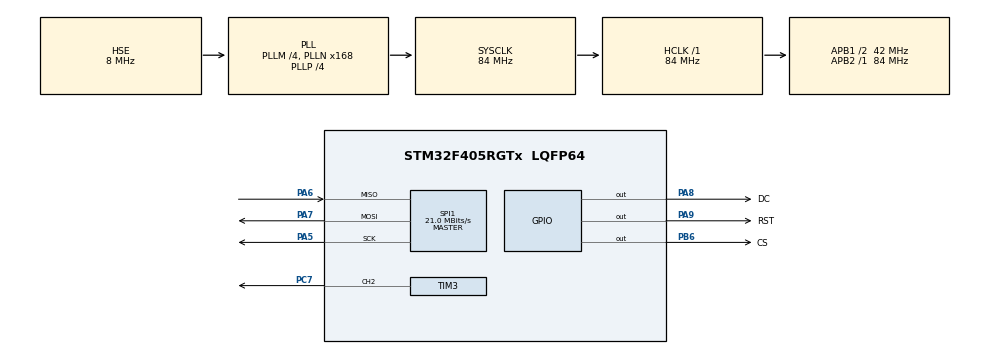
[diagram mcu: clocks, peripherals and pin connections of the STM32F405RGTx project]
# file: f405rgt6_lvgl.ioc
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FREERTOS.Tasks01=defaultTask,24,128,StartDefaultTask,Default,NULL,Dynamic,NULL,NULL
Mcu.Family=STM32F4
Mcu.Name=STM32F405RGTx
Mcu.Package=LQFP64
NVIC.PriorityGroup=NVIC_PRIORITYGROUP_4
NVIC.TIM1_UP_TIM10_IRQn=true\:15\:0\:false\:false\:true\:false\:false\:true\:true
NVIC.TimeBase=TIM1_UP_TIM10_IRQn
NVIC.TimeBaseIP=TIM1
PA5.Mode=Full_Duplex_Master
PA5.Signal=SPI1_SCK
PA6.Mode=Full_Duplex_Master
PA6.Signal=SPI1_MISO
PA7.Mode=Full_Duplex_Master
PA7.Signal=SPI1_MOSI
PA8.GPIO_Label=DC
PA8.PinState=GPIO_PIN_SET
PA8.Signal=GPIO_Output
PA9.GPIO_Label=RST
PA9.PinState=GPIO_PIN_SET
PA9.Signal=GPIO_Output
PB6.GPIO_Label=CS
PB6.PinState=GPIO_PIN_SET
PB6.Signal=GPIO_Output
PC14-OSC32_IN.Mode=LSE-External-Oscillator
PC14-OSC32_IN.Signal=RCC_OSC32_IN
PC15-OSC32_OUT.Mode=LSE-External-Oscillator
PC15-OSC32_OUT.Signal=RCC_OSC32_OUT
PC7.Signal=S_TIM3_CH2
PH0-OSC_IN.Mode=HSE-External-Oscillator
PH0-OSC_IN.Signal=RCC_OSC_IN
PH1-OSC_OUT.Mode=HSE-External-Oscillator
PH1-OSC_OUT.Signal=RCC_OSC_OUT
ProjectManager.HeapSize=0x200
ProjectManager.StackSize=0x400
ProjectManager.TargetToolchain=Makefile
RCC.48MHZClocksFreq_Value=84000000
RCC.AHBFreq_Value=84000000
RCC.APB1CLKDivider=RCC_HCLK_DIV2
RCC.APB1Freq_Value=42000000
RCC.APB1TimFreq_Value=84000000
RCC.APB2Freq_Value=84000000
RCC.APB2TimFreq_Value=84000000
RCC.CortexFreq_Value=84000000
RCC.HCLKFreq_Value=84000000
RCC.HSE_VALUE=8000000
RCC.HSI_VALUE=16000000
RCC.PLLM=4
RCC.PLLN=168
RCC.PLLP=RCC_PLLP_DIV4
RCC.PLLSourceVirtual=RCC_PLLSOURCE_HSE
RCC.SYSCLKFreq_VALUE=84000000
RCC.SYSCLKSource=RCC_SYSCLKSOURCE_PLLCLK
RCC.VCOOutputFreq_Value=336000000
SH.S_TIM3_CH2.0=TIM3_CH2,PWM Generation2 CH2
SPI1.BaudRatePrescaler=SPI_BAUDRATEPRESCALER_4
SPI1.CLKPolarity=SPI_POLARITY_LOW
SPI1.CalculateBaudRate=21.0 MBits/s
SPI1.DataSize=SPI_DATASIZE_8BIT
SPI1.Direction=SPI_DIRECTION_2LINES
SPI1.Mode=SPI_MODE_MASTER
SPI1.VirtualType=VM_MASTER
TIM3.Channel-PWM\ Generation2\ CH2=TIM_CHANNEL_2
TIM3.Period=1000-1
TIM3.Prescaler=300-1
VP_FREERTOS_VS_CMSIS_V2.Mode=CMSIS_V2
VP_SYS_VS_tim1.Mode=TIM1
board=custom

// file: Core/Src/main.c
/* USER CODE BEGIN Header */
/**
  ******************************************************************************
  * @file           : main.c
  * @brief          : Main program body
  ******************************************************************************
  * @attention
  *
  * Copyright (c) 2024 STMicroelectronics.
  * All rights reserved.
  *
  * This software is licensed under terms that can be found in the LICENSE file
  * in the root directory of this software component.
  * If no LICENSE file comes with this software, it is provided AS-IS.
  *
  ******************************************************************************
  */
/* USER CODE END Header */
#include "main.h"
#include "cmsis_os.h"
#include "spi.h"
#include "tim.h"
#include "gpio.h"

void SystemClock_Config(void);
void MX_FREERTOS_Init(void);

int main(void)
{
  /* USER CODE BEGIN 1 */
  __HAL_RCC_HSI_ENABLE();
  __HAL_RCC_SYSCLK_CONFIG(RCC_SYSCLKSOURCE_HSI);
  /* USER CODE END 1 */

  /* MCU Configuration--------------------------------------------------------*/

  /* Reset of all peripherals, Initializes the Flash interface and the Systick. */
  HAL_Init();

  /* Configure the system clock */
  SystemClock_Config();

  /* Initialize all configured peripherals */
  MX_GPIO_Init();
  MX_SPI1_Init();
  MX_TIM3_Init();
  /* USER CODE BEGIN 2 */
//  LCD_1in28_test();

  /* USER CODE END 2 */

  /* Init scheduler */
  osKernelInitialize();

  /* Call init function for freertos objects (in freertos.c) */
  MX_FREERTOS_Init();

  /* Start scheduler */
  osKernelStart();

  /* We should never get here as control is now taken by the scheduler */
  /* Infinite loop */
  while (1) {

  }
}

void SystemClock_Config(void)
{
  RCC_OscInitTypeDef RCC_OscInitStruct = {0};
  RCC_ClkInitTypeDef RCC_ClkInitStruct = {0};

  /** Configure the main internal regulator output voltage
  */
  __HAL_RCC_PWR_CLK_ENABLE();
  __HAL_PWR_VOLTAGESCALING_CONFIG(PWR_REGULATOR_VOLTAGE_SCALE1);

  /** Initializes the RCC Oscillators according to the specified parameters
  * in the RCC_OscInitTypeDef structure.
  */
  RCC_OscInitStruct.OscillatorType = RCC_OSCILLATORTYPE_HSE;
  RCC_OscInitStruct.HSEState = RCC_HSE_ON;
  RCC_OscInitStruct.PLL.PLLState = RCC_PLL_ON;
  RCC_OscInitStruct.PLL.PLLSource = RCC_PLLSOURCE_HSE;
  RCC_OscInitStruct.PLL.PLLM = 4;
  RCC_OscInitStruct.PLL.PLLN = 168;
  RCC_OscInitStruct.PLL.PLLP = RCC_PLLP_DIV4;
  RCC_OscInitStruct.PLL.PLLQ = 4;
  if (HAL_RCC_OscConfig(&RCC_OscInitStruct) != HAL_OK)
  {
    Error_Handler();
  }

  /** Initializes the CPU, AHB and APB buses clocks
  */
  RCC_ClkInitStruct.ClockType = RCC_CLOCKTYPE_HCLK|RCC_CLOCKTYPE_SYSCLK
                              |RCC_CLOCKTYPE_PCLK1|RCC_CLOCKTYPE_PCLK2;
  RCC_ClkInitStruct.SYSCLKSource = RCC_SYSCLKSOURCE_PLLCLK;
  RCC_ClkInitStruct.AHBCLKDivider = RCC_SYSCLK_DIV1;
  RCC_ClkInitStruct.APB1CLKDivider = RCC_HCLK_DIV2;
  RCC_ClkInitStruct.APB2CLKDivider = RCC_HCLK_DIV1;

  if (HAL_RCC_ClockConfig(&RCC_ClkInitStruct, FLASH_LATENCY_2) != HAL_OK)
  {
    Error_Handler();
  }
}

void HAL_TIM_PeriodElapsedCallback(TIM_HandleTypeDef *htim)
{
  if (htim->Instance == TIM1) {
    HAL_IncTick();
  }
}

void Error_Handler(void)
{
  __disable_irq();
  while (1) {
  }
}

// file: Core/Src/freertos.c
/* USER CODE BEGIN Header */
/**
  ******************************************************************************
  * File Name          : freertos.c
  * Description        : Code for freertos applications
  ******************************************************************************
  * @attention
  *
  * Copyright (c) 2024 STMicroelectronics.
  * All rights reserved.
  *
  * This software is licensed under terms that can be found in the LICENSE file
  * in the root directory of this software component.
  * If no LICENSE file comes with this software, it is provided AS-IS.
  *
  ******************************************************************************
  */
/* USER CODE END Header */

#include "FreeRTOS.h"
#include "task.h"
#include "main.h"
#include "cmsis_os.h"

/* Definitions for defaultTask */
//osThreadId_t defaultTaskHandle;
//const osThreadAttr_t defaultTask_attributes = {
//  .name = "defaultTask",
//  .stack_size = 128 * 4,
//  .priority = (osPriority_t) osPriorityNormal,
//};

//void StartDefaultTask(void *argument);

_Noreturn void MX_FREERTOS_Init(void); /* (MISRA C 2004 rule 8.1) */

_Noreturn __weak void MX_FREERTOS_Init(void) {
/* USER CODE BEGIN Header */
/**
  ******************************************************************************
  * File Name          :
  * Description        :
  ******************************************************************************
  * @attention
  *
  * Copyright (c) 2024 STMicroelectronics.
  * All rights reserved.
  *
  * This software is licensed under terms that can be found in the LICENSE file
  * in the root directory of this software component.
  * If no LICENSE file comes with this software, it is provided AS-IS.
  *
  ******************************************************************************
  */
/* USER CODE END Header */

}

//void StartDefaultTask(void *argument)
//{
//  /* USER CODE BEGIN StartDefaultTask */
//  /* Infinite loop */
//  for(;;)
//  {
//    osDelay(1);
//  }
//  /* USER CODE END StartDefaultTask */
//}
